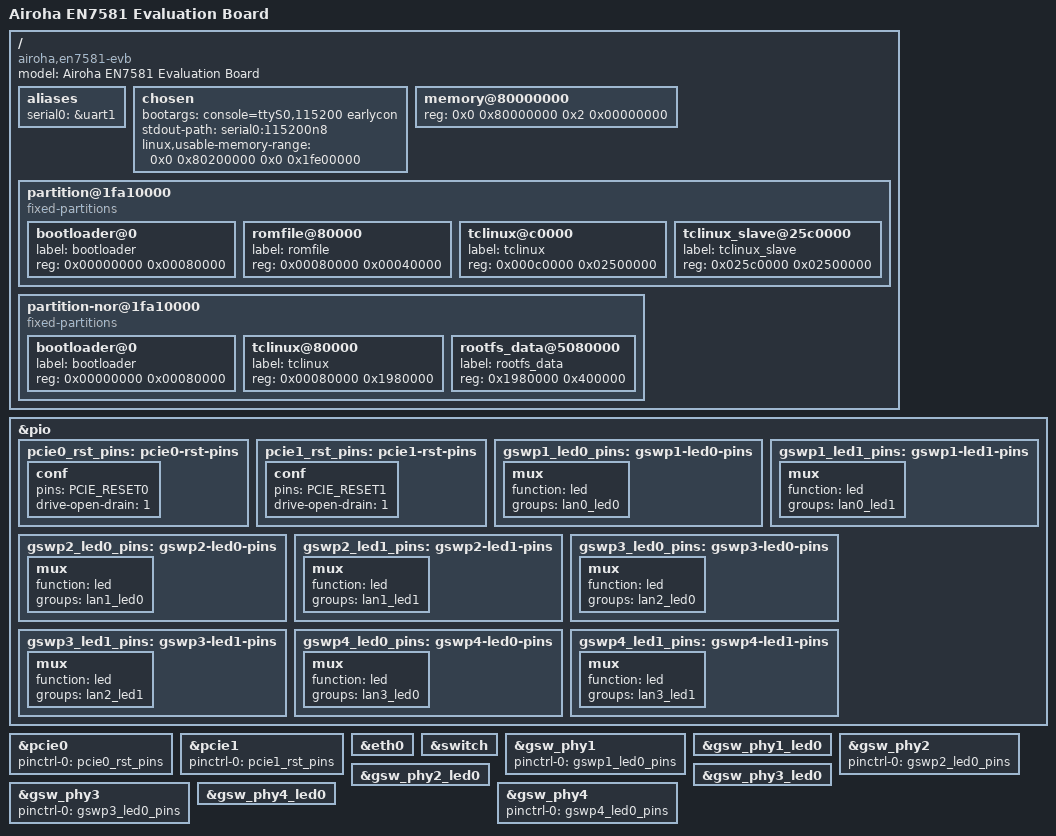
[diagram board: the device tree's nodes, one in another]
// SPDX-License-Identifier: (GPL-2.0-only OR BSD-2-Clause)
/dts-v1/;

/* Bootloader installs ATF here */
/memreserve/ 0x80000000 0x200000;

#include <dt-bindings/leds/common.h>
#include "en7581.dtsi"

/ {
	model = "Airoha EN7581 Evaluation Board";
	compatible = "airoha,en7581-evb", "airoha,en7581";

	aliases {
		serial0 = &uart1;
	};

	chosen {
		bootargs = "console=ttyS0,115200 earlycon";
		stdout-path = "serial0:115200n8";
		linux,usable-memory-range = <0x0 0x80200000 0x0 0x1fe00000>;
	};

	memory@80000000 {
		device_type = "memory";
		reg = <0x0 0x80000000 0x2 0x00000000>;
	};

	partition@1fa10000 {
		compatible = "fixed-partitions";
		#address-cells = <1>;
		#size-cells = <1>;

		bootloader@0 {
			label = "bootloader";
			reg = <0x00000000 0x00080000>;
		};
		romfile@80000 {
			label = "romfile";
			reg = <0x00080000 0x00040000>;
		};
		tclinux@c0000 {
			label = "tclinux";
			reg = <0x000c0000 0x02500000>;
		};
		tclinux_slave@25c0000 {
			label = "tclinux_slave";
			reg = <0x025c0000 0x02500000>;
		};
	};

	partition-nor@1fa10000 {
		compatible = "fixed-partitions";
		#address-cells = <1>;
		#size-cells = <1>;

		bootloader@0 {
			label = "bootloader";
			reg = <0x00000000 0x00080000>;
		};
		tclinux@80000 {
			label = "tclinux";
			reg = <0x00080000 0x1980000>;
		};
		rootfs_data@5080000 {
			label = "rootfs_data";
			reg = <0x1980000 0x400000>;
		};
	};
};

&pio {
	pcie0_rst_pins: pcie0-rst-pins {
		conf {
			pins = "PCIE_RESET0";
			drive-open-drain = <1>;
		};
	};

	pcie1_rst_pins: pcie1-rst-pins {
		conf {
			pins = "PCIE_RESET1";
			drive-open-drain = <1>;
		};
	};

	gswp1_led0_pins: gswp1-led0-pins {
		mux {
			function = "led";
			groups = "lan0_led0";
		};
	};

	gswp1_led1_pins: gswp1-led1-pins {
		mux {
			function = "led";
			groups = "lan0_led1";
		};
	};

	gswp2_led0_pins: gswp2-led0-pins {
		mux {
			function = "led";
			groups = "lan1_led0";
		};
	};

	gswp2_led1_pins: gswp2-led1-pins {
		mux {
			function = "led";
			groups = "lan1_led1";
		};
	};

	gswp3_led0_pins: gswp3-led0-pins {
		mux {
			function = "led";
			groups = "lan2_led0";
		};
	};

	gswp3_led1_pins: gswp3-led1-pins {
		mux {
			function = "led";
			groups = "lan2_led1";
		};
	};

	gswp4_led0_pins: gswp4-led0-pins {
		mux {
			function = "led";
			groups = "lan3_led0";
		};
	};

	gswp4_led1_pins: gswp4-led1-pins {
		mux {
			function = "led";
			groups = "lan3_led1";
		};
	};
};

&pcie0 {
	pinctrl-names = "default";
	pinctrl-0 = <&pcie0_rst_pins>;
	status = "okay";
};

&pcie1 {
	pinctrl-names = "default";
	pinctrl-0 = <&pcie1_rst_pins>;
	status = "okay";
};

&eth0 {
	status = "okay";
};

&switch {
	status = "okay";
};

&gsw_phy1 {
	pinctrl-names = "led";
	pinctrl-0 = <&gswp1_led0_pins>;
	status = "okay";
};

&gsw_phy1_led0 {
	status = "okay";
};

&gsw_phy2 {
	pinctrl-names = "led";
	pinctrl-0 = <&gswp2_led0_pins>;
	status = "okay";
};

&gsw_phy2_led0 {
	status = "okay";
};

&gsw_phy3 {
	pinctrl-names = "led";
	pinctrl-0 = <&gswp3_led0_pins>;
	status = "okay";
};

&gsw_phy3_led0 {
	status = "okay";
};

&gsw_phy4 {
	pinctrl-names = "led";
	pinctrl-0 = <&gswp4_led0_pins>;
	status = "okay";
};

&gsw_phy4_led0 {
	status = "okay";
};
